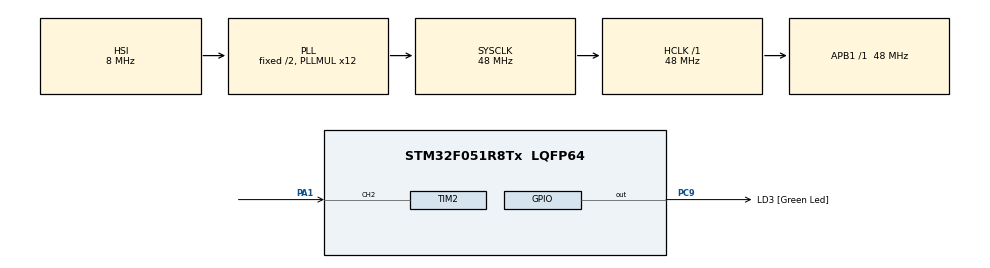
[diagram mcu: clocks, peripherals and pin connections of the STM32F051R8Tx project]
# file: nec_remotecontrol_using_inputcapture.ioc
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Mcu.Family=STM32F0
Mcu.Name=STM32F051R8Tx
Mcu.Package=LQFP64
NVIC.TIM2_IRQn=true\:0\:0\:false\:false\:true\:true\:true
PA1.GPIO_Speed=GPIO_SPEED_FREQ_HIGH
PA1.Signal=S_TIM2_CH2
PC9.GPIO_Label=LD3 [Green Led]
PC9.Signal=GPIO_Output
ProjectManager.HeapSize=0x200
ProjectManager.StackSize=0x400
ProjectManager.TargetToolchain=MDK-ARM V5
RCC.AHBFreq_Value=48000000
RCC.APB1Freq_Value=48000000
RCC.APB1TimFreq_Value=48000000
RCC.HCLKFreq_Value=48000000
RCC.PLLMUL=RCC_PLL_MUL12
RCC.SYSCLKFreq_VALUE=48000000
RCC.SYSCLKSource=RCC_SYSCLKSOURCE_PLLCLK
SH.S_TIM2_CH2.0=TIM2_CH2,Input_Capture2_from_TI2
TIM2.Channel-Input_Capture2_from_TI2=TIM_CHANNEL_2
TIM2.ICFilter_CH2=15
TIM2.ICPolarity_CH2=TIM_INPUTCHANNELPOLARITY_FALLING
TIM2.Period=100000
TIM2.Prescaler=48-1
VP_TIM2_VS_ClockSourceINT.Mode=Internal
board=STM32F0DISCOVERY

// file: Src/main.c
/* USER CODE BEGIN Header */
/**
  ******************************************************************************
  * @file           : main.c
  * @brief          : Main program body
  ******************************************************************************
  * @attention
  *
  * <h2><center>&copy; Copyright (c) 2019 STMicroelectronics.
  * All rights reserved.</center></h2>
  *
  * This software component is licensed by ST under BSD 3-Clause license,
  * the "License"; You may not use this file except in compliance with the
  * License. You may obtain a copy of the License at:
  *                        opensource.org/licenses/BSD-3-Clause
  *
  ******************************************************************************
  */
/* USER CODE END Header */

#include "main.h"

/* USER CODE BEGIN Includes */
#include "stm32f0xx_hal.h"

/* USER CODE END Includes */

/* USER CODE BEGIN PTD */
//#define IR_DEBUG__LOG

#define IR_PERCENT(b)   (b>>2)      // +/-%4 of the bit timing
#define IR_DELTA(a, b) (((b+IR_PERCENT(b)) > (a)) && ((b-IR_PERCENT(b)) < (a)))
#define IR_BIT__LEADING             (9000U)
#define IR_BIT__SPACE               (4500U)
#define IR_BIT__START_FRAME         (IR_BIT__LEADING+IR_BIT__SPACE)
#define IR_BIT__LOW                 (1250U)
#define IR_BIT__HIGH                (2250U)
#define IR_CODE__ADDR_GET(a)        (a & 0xFF)
#define IR_CODE__CMD_GET(a)         ((a>>16) & 0xFF)
/* USER CODE END PTD */

TIM_HandleTypeDef htim2;

/* USER CODE BEGIN PV */
/* Private variables ---------------------------------------------------------*/

#ifdef IR_DEBUG__LOG
#define BUFFER_SIZE     256
//need to be global, otherwise will not show on watch.
uint32_t icChn[BUFFER_SIZE];
uint32_t icCnt=0U;
volatile uint32_t irCode=0;          //store the 32 bits ircode include addr/~addr command/~command
volatile uint32_t irNewCode=0;
volatile uint32_t irBitCnt=0;
volatile uint32_t irCodeDetect=0;
volatile uint16_t irLow;
volatile uint16_t irHigh;
volatile uint8_t  irAddr;
volatile uint8_t  irCmd;
volatile uint32_t icVal=0U;
#else
static volatile uint32_t irCode=0;          //store the 32 bits ircode include addr/~addr command/~command
static volatile uint32_t irNewCode=0;
static volatile uint32_t irBitCnt=0;
static volatile uint32_t irCodeDetect=0;
static volatile uint16_t irLow;
static volatile uint16_t irHigh;
static volatile uint8_t  irAddr;
static volatile uint8_t  irCmd;
static volatile uint32_t icVal=0U;
#endif
/* USER CODE END PV */

void SystemClock_Config(void);
static void MX_GPIO_Init(void);
static void MX_TIM2_Init(void);
/* USER CODE BEGIN PFP */
/* Private function prototypes -----------------------------------------------*/

/* USER CODE END PFP */

/* USER CODE BEGIN 0 */
void HAL_TIM_IC_CaptureCallback(TIM_HandleTypeDef *htim)
{
    if (htim->Instance == TIM2) {
        icVal = HAL_TIM_ReadCapturedValue(htim, TIM_CHANNEL_2);

        //should be 9ms+4.5ms = 13.5ms
        if (IR_DELTA(icVal, IR_BIT__START_FRAME)) {
            irBitCnt=2;  //two pulse added
            irCode=0;
        }
        else if (irBitCnt >= 0x02) {
            //save irbit
            //1.25ms
            irLow = IR_DELTA(icVal, IR_BIT__LOW);
            //2.25ms
            irHigh = IR_DELTA(icVal, IR_BIT__HIGH);
            if (irLow || irHigh) {
                irBitCnt++;
                irCode <<= 1;
                if (irHigh) {
                    irCode |= 1;
                }
            } else {
                //the ir data is not valid
                //reset the state
                irBitCnt=0;
                irCode = 0;
            }

            //Detect the ir command and data
            if (irBitCnt >= 32) {
                irNewCode = irCode;
                irAddr = IR_CODE__ADDR_GET(irNewCode);
                irCmd = IR_CODE__CMD_GET(irNewCode);
                irBitCnt=0;
                irCode = 0;
                //should copy the irCode to the user.
            }
        }
        __HAL_TIM_SET_COUNTER(htim,0);

#ifdef IR_DEBUG__LOG
        //Log the timing for debugging purpose
        if (icVal) {
            if (icVal > BUFFER_SIZE) icVal = 0; //wrap around
            icChn[icCnt++] = icVal;
        }
#endif
    }
}

/* USER CODE END 0 */

int main(void)
{

  /* MCU Configuration--------------------------------------------------------*/

  /* Reset of all peripherals, Initializes the Flash interface and the Systick. */
  HAL_Init();

  /* USER CODE BEGIN Init */
#ifdef IR_DEBUG__LOG
    for (int i=0; i < BUFFER_SIZE; i++) {
       icChn[i] = 0;
    }
#endif
  /* USER CODE END Init */

  /* Configure the system clock */
  SystemClock_Config();

  /* Initialize all configured peripherals */
  MX_GPIO_Init();
  MX_TIM2_Init();
  /* USER CODE BEGIN 2 */
  HAL_TIM_IC_Start_IT(&htim2, TIM_CHANNEL_2);
  /* USER CODE END 2 */

  /* Infinite loop */
  while (1)
  {

    /* USER CODE BEGIN 3 */
  HAL_GPIO_TogglePin(GPIOC, GPIO_PIN_9);
  HAL_Delay(200);
  }
  /* USER CODE END 3 */
}

void SystemClock_Config(void)
{
  RCC_OscInitTypeDef RCC_OscInitStruct = {0};
  RCC_ClkInitTypeDef RCC_ClkInitStruct = {0};

  /** Initializes the CPU, AHB and APB busses clocks
  */
  RCC_OscInitStruct.OscillatorType = RCC_OSCILLATORTYPE_HSI;
  RCC_OscInitStruct.HSIState = RCC_HSI_ON;
  RCC_OscInitStruct.HSICalibrationValue = RCC_HSICALIBRATION_DEFAULT;
  RCC_OscInitStruct.PLL.PLLState = RCC_PLL_ON;
  RCC_OscInitStruct.PLL.PLLSource = RCC_PLLSOURCE_HSI;
  RCC_OscInitStruct.PLL.PLLMUL = RCC_PLL_MUL12;
  RCC_OscInitStruct.PLL.PREDIV = RCC_PREDIV_DIV1;
  if (HAL_RCC_OscConfig(&RCC_OscInitStruct) != HAL_OK)
  {
    Error_Handler();
  }
  /** Initializes the CPU, AHB and APB busses clocks
  */
  RCC_ClkInitStruct.ClockType = RCC_CLOCKTYPE_HCLK|RCC_CLOCKTYPE_SYSCLK
                              |RCC_CLOCKTYPE_PCLK1;
  RCC_ClkInitStruct.SYSCLKSource = RCC_SYSCLKSOURCE_PLLCLK;
  RCC_ClkInitStruct.AHBCLKDivider = RCC_SYSCLK_DIV1;
  RCC_ClkInitStruct.APB1CLKDivider = RCC_HCLK_DIV1;

  if (HAL_RCC_ClockConfig(&RCC_ClkInitStruct, FLASH_LATENCY_1) != HAL_OK)
  {
    Error_Handler();
  }
}

static void MX_TIM2_Init(void)
{

  TIM_ClockConfigTypeDef sClockSourceConfig = {0};
  TIM_MasterConfigTypeDef sMasterConfig = {0};
  TIM_IC_InitTypeDef sConfigIC = {0};

  htim2.Instance = TIM2;
  htim2.Init.Prescaler = 48-1;
  htim2.Init.CounterMode = TIM_COUNTERMODE_UP;
  htim2.Init.Period = 100000;
  htim2.Init.ClockDivision = TIM_CLOCKDIVISION_DIV1;
  htim2.Init.AutoReloadPreload = TIM_AUTORELOAD_PRELOAD_DISABLE;
  if (HAL_TIM_Base_Init(&htim2) != HAL_OK)
  {
    Error_Handler();
  }
  sClockSourceConfig.ClockSource = TIM_CLOCKSOURCE_INTERNAL;
  if (HAL_TIM_ConfigClockSource(&htim2, &sClockSourceConfig) != HAL_OK)
  {
    Error_Handler();
  }
  if (HAL_TIM_IC_Init(&htim2) != HAL_OK)
  {
    Error_Handler();
  }
  sMasterConfig.MasterOutputTrigger = TIM_TRGO_RESET;
  sMasterConfig.MasterSlaveMode = TIM_MASTERSLAVEMODE_DISABLE;
  if (HAL_TIMEx_MasterConfigSynchronization(&htim2, &sMasterConfig) != HAL_OK)
  {
    Error_Handler();
  }
  sConfigIC.ICPolarity = TIM_INPUTCHANNELPOLARITY_FALLING;
  sConfigIC.ICSelection = TIM_ICSELECTION_DIRECTTI;
  sConfigIC.ICPrescaler = TIM_ICPSC_DIV1;
  sConfigIC.ICFilter = 15;
  if (HAL_TIM_IC_ConfigChannel(&htim2, &sConfigIC, TIM_CHANNEL_2) != HAL_OK)
  {
    Error_Handler();
  }

}

static void MX_GPIO_Init(void)
{
  GPIO_InitTypeDef GPIO_InitStruct = {0};

  /* GPIO Ports Clock Enable */
  __HAL_RCC_GPIOA_CLK_ENABLE();
  __HAL_RCC_GPIOC_CLK_ENABLE();

  /*Configure GPIO pin Output Level */
  HAL_GPIO_WritePin(LD3_GPIO_Port, LD3_Pin, GPIO_PIN_RESET);

  /*Configure GPIO pin : LD3_Pin */
  GPIO_InitStruct.Pin = LD3_Pin;
  GPIO_InitStruct.Mode = GPIO_MODE_OUTPUT_PP;
  GPIO_InitStruct.Pull = GPIO_NOPULL;
  GPIO_InitStruct.Speed = GPIO_SPEED_FREQ_LOW;
  HAL_GPIO_Init(LD3_GPIO_Port, &GPIO_InitStruct);

}

void Error_Handler(void)
{
  while(1)
  {
  }
}

/************************ (C) COPYRIGHT STMicroelectronics *****END OF FILE****/
